# CH32X035 register map
Vendor: WCH Ltd.; File version: 1.0
Registers are 32-bit, read-write, reset 0x0 unless marked. A register's access mark holds for its fields unless they carry their own. Offsets are from the block's base; [hi:lo] are bit positions.

## IWDG — Independent watchdog
Base 0x40003000
0x00 CTLR 16-bit wo — Key register (IWDG_CTLR)
  [15:0] KEY — Key value
0x04 PSCR 16-bit — Prescaler register (IWDG_PSCR)
  [2:0] PR — Prescaler divider
0x08 RLDR 16-bit reset 0xFFF — Reload register (IWDG_RLDR)
  [11:0] RL — Watchdog counter reload value
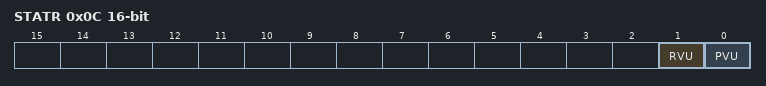
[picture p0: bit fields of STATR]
0x0C STATR 16-bit ro — Status register (IWDG_SR)
  [1] RVU — Watchdog counter reload value update
  [0] PVU — Watchdog prescaler value update

## WWDG — Window watchdog
Base 0x40002C00
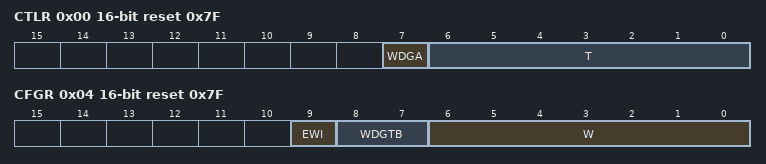
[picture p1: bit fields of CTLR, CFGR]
0x00 CTLR 16-bit reset 0x7F — Control register (WWDG_CR)
  [7] WDGA — Activation bit
  [6:0] T — 7-bit counter (MSB to LSB)
0x04 CFGR 16-bit access per field reset 0x7F — Configuration register (WWDG_CFR)
  [9] EWI read/set — Early Wakeup Interrupt
  [8:7] WDGTB rw — Timer Base
  [6:0] W rw — 7-bit window value
0x08 STATR 16-bit read/clear — Status register (WWDG_SR)
  [0] EWIF — Early Wakeup Interrupt Flag

## TIM3 — General purpose timer
Base 0x40000400
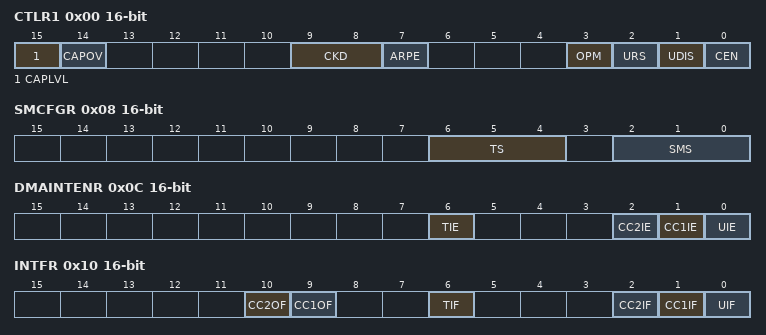
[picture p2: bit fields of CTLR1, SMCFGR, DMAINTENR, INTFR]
0x00 CTLR1 16-bit — control register 1
  [15] CAPLVL
  [14] CAPOV
  [9:8] CKD — Clock division
  [7] ARPE — Auto-reload preload enable
  [3] OPM — One-pulse mode
  [2] URS — Update request source
  [1] UDIS — Update disable
  [0] CEN — Counter enable
0x08 SMCFGR 16-bit — slave mode control register
  [6:4] TS — Trigger selection
  [2:0] SMS — Slave mode selection
0x0C DMAINTENR 16-bit — DMA/Interrupt enable register
  [6] TIE — Trigger interrupt enable
  [2] CC2IE — Capture/Compare 2 interrupt enable
  [1] CC1IE — Capture/Compare 1 interrupt enable
  [0] UIE — Update interrupt enable
0x10 INTFR 16-bit wo — status register
  [10] CC2OF — Capture/compare 2 overcapture flag
  [9] CC1OF — Capture/Compare 1 overcapture flag
  [6] TIF — Trigger interrupt flag
  [2] CC2IF — Capture/Compare 2 interrupt flag
  [1] CC1IF — Capture/compare 1 interrupt flag
  [0] UIF — Update interrupt flag
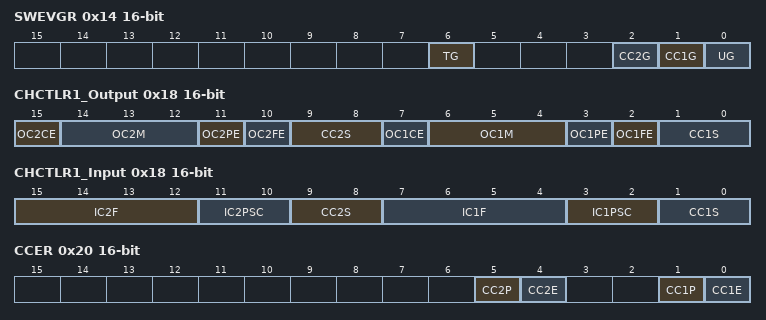
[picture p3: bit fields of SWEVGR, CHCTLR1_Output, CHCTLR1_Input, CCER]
0x14 SWEVGR 16-bit wo — event generation register
  [6] TG — Trigger generation
  [2] CC2G — Capture/compare 2 generation
  [1] CC1G — Capture/compare 1 generation
  [0] UG — Update generation
0x18 CHCTLR1_Output 16-bit — capture/compare mode register 1 (output mode)
  [15] OC2CE — Output compare 2 clear enable
  [14:12] OC2M — Output compare 2 mode
  [11] OC2PE — Output compare 2 preload enable
  [10] OC2FE — Output compare 2 fast enable
  [9:8] CC2S — Capture/Compare 2 selection
  [7] OC1CE — Output compare 1 clear enable
  [6:4] OC1M — Output compare 1 mode
  [3] OC1PE — Output compare 1 preload enable
  [2] OC1FE — Output compare 1 fast enable
  [1:0] CC1S — Capture/Compare 1 selection
0x18 CHCTLR1_Input 16-bit (alternate view of CHCTLR1_Output) — capture/compare mode register 1 (input mode)
  [15:12] IC2F — Input capture 2 filter
  [11:10] IC2PSC — Input capture 2 prescaler
  [9:8] CC2S — Capture/compare 2 selection
  [7:4] IC1F — Input capture 1 filter
  [3:2] IC1PSC — Input capture 1 prescaler
  [1:0] CC1S — Capture/Compare 1 selection
0x20 CCER 16-bit — capture/compare enable register
  [5] CC2P — Capture/Compare 2 output Polarity
  [4] CC2E — Capture/Compare 2 output enable
  [1] CC1P — Capture/Compare 1 output Polarity
  [0] CC1E — Capture/Compare 1 output enable
0x24 CNT 16-bit — counter
  [15:0] CNT — counter value
0x28 PSC 16-bit — prescaler
  [15:0] PSC — Prescaler value
0x2C ATRLR 16-bit — auto-reload register
  [15:0] ATRLR — Auto-reload value
0x34 CH1CVR 16-bit — capture/compare register 1
  [15:0] CH1CVR — Capture/Compare 1 value
0x38 CH2CVR 16-bit — capture/compare register 2
  [15:0] CH2CVR — Capture/Compare 2 value
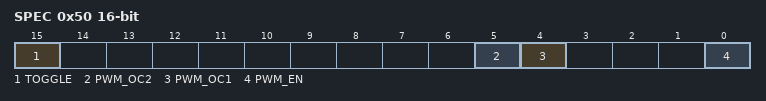
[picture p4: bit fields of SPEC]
0x50 SPEC 16-bit access per field
  [15] TOGGLE ro, [5] PWM_OC2 rw, [4] PWM_OC1 rw, [0] PWM_EN rw

## I2C1 — Inter integrated circuit
Base 0x40005400
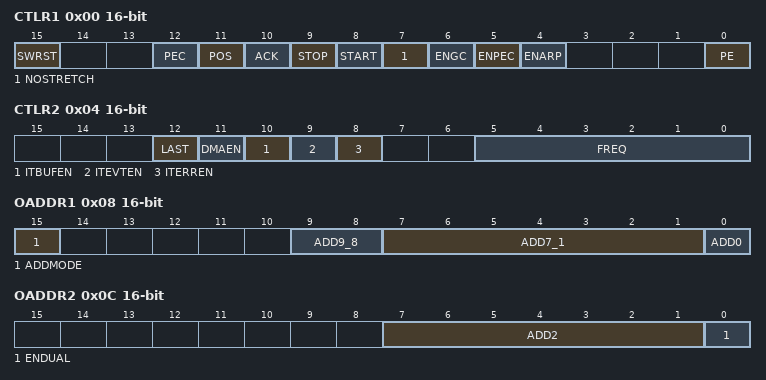
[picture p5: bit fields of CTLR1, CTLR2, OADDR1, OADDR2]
0x00 CTLR1 16-bit — Control register 1
  [15] SWRST — Software reset
  [12] PEC — Packet error checking
  [11] POS — Acknowledge/PEC Position (for data reception)
  [10] ACK — Acknowledge enable
  [9] STOP — Stop generation
  [8] START — Start generation
  [7] NOSTRETCH — Clock stretching disable (Slave mode)
  [6] ENGC — General call enable
  [5] ENPEC — PEC enable
  [4] ENARP — ARP enable
  [0] PE — Peripheral enable
0x04 CTLR2 16-bit — Control register 2
  [12] LAST — DMA last transfer
  [11] DMAEN — DMA requests enable
  [10] ITBUFEN — Buffer interrupt enable
  [9] ITEVTEN — Event interrupt enable
  [8] ITERREN — Error interrupt enable
  [5:0] FREQ — Peripheral clock frequency
0x08 OADDR1 16-bit — Own address register 1
  [15] ADDMODE — Addressing mode (slave mode)
  [9:8] ADD9_8 — Interface address
  [7:1] ADD7_1 — Interface address
  [0] ADD0 — Interface address
0x0C OADDR2 16-bit — Own address register 2
  [7:1] ADD2 — Interface address
  [0] ENDUAL — Dual addressing mode enable
0x10 DATAR 16-bit — Data register
  [7:0] DATAR — 8-bit data register
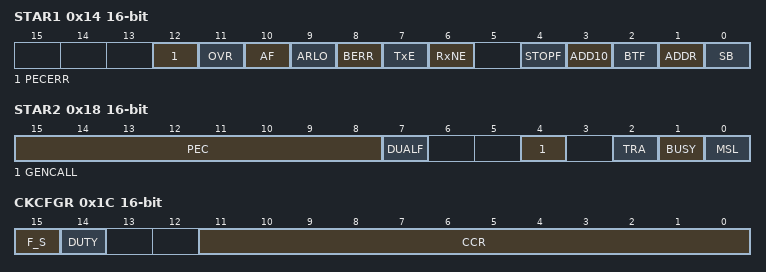
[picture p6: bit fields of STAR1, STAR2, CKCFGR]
0x14 STAR1 16-bit access per field — Status register 1
  [12] PECERR read/clear — PEC Error in reception
  [11] OVR read/clear — Overrun/Underrun
  [10] AF read/clear — Acknowledge failure
  [9] ARLO read/clear — Arbitration lost (master mode)
  [8] BERR read/clear — Bus error
  [7] TxE ro — Data register empty (transmitters)
  [6] RxNE ro — Data register not empty (receivers)
  [4] STOPF ro — Stop detection (slave mode)
  [3] ADD10 ro — 10-bit header sent (Master mode)
  [2] BTF ro — Byte transfer finished
  [1] ADDR read/clear — Address sent (master mode)/matched (slave mode)
  [0] SB ro — Start bit (Master mode)
0x18 STAR2 16-bit ro — Status register 2
  [15:8] PEC
  [7] DUALF — Dual flag (Slave mode)
  [4] GENCALL — General call address (Slave mode)
  [2] TRA — Transmitter/receiver
  [1] BUSY — Bus busy
  [0] MSL — Master/slave
0x1C CKCFGR 16-bit — Clock control register
  [15] F_S — I2C master mode selection
  [14] DUTY — Fast mode duty cycle
  [11:0] CCR — Clock control register in Fast/Standard mode (Master mode)
